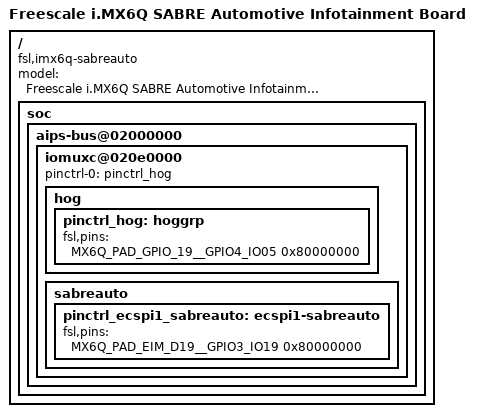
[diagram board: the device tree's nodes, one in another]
/*
 * Copyright 2013 Freescale Semiconductor, Inc.
 *
 * This program is free software; you can redistribute it and/or modify
 * it under the terms of the GNU General Public License version 2 as
 * published by the Free Software Foundation.
 *
 */

/dts-v1/;
#include "imx6q.dtsi"
#include "imx6qdl-sabreauto.dtsi"

/ {
	model = "Freescale i.MX6Q SABRE Automotive Infotainment Board";
	compatible = "fsl,imx6q-sabreauto", "fsl,imx6q";

	soc {
		aips-bus@02000000 { /* AIPS1 */
			iomuxc@020e0000 {
				pinctrl-names = "default";
				pinctrl-0 = <&pinctrl_hog>;

				hog {
					pinctrl_hog: hoggrp {
						fsl,pins = <
							/*RGMII Phy Interrupt */
							MX6Q_PAD_GPIO_19__GPIO4_IO05 0x80000000
						>;
					};
				};

				sabreauto {
					pinctrl_ecspi1_sabreauto: ecspi1-sabreauto {
						fsl,pins = <
							MX6Q_PAD_EIM_D19__GPIO3_IO19 0x80000000
						>;
					};
				};
			};
		};
	};
};
